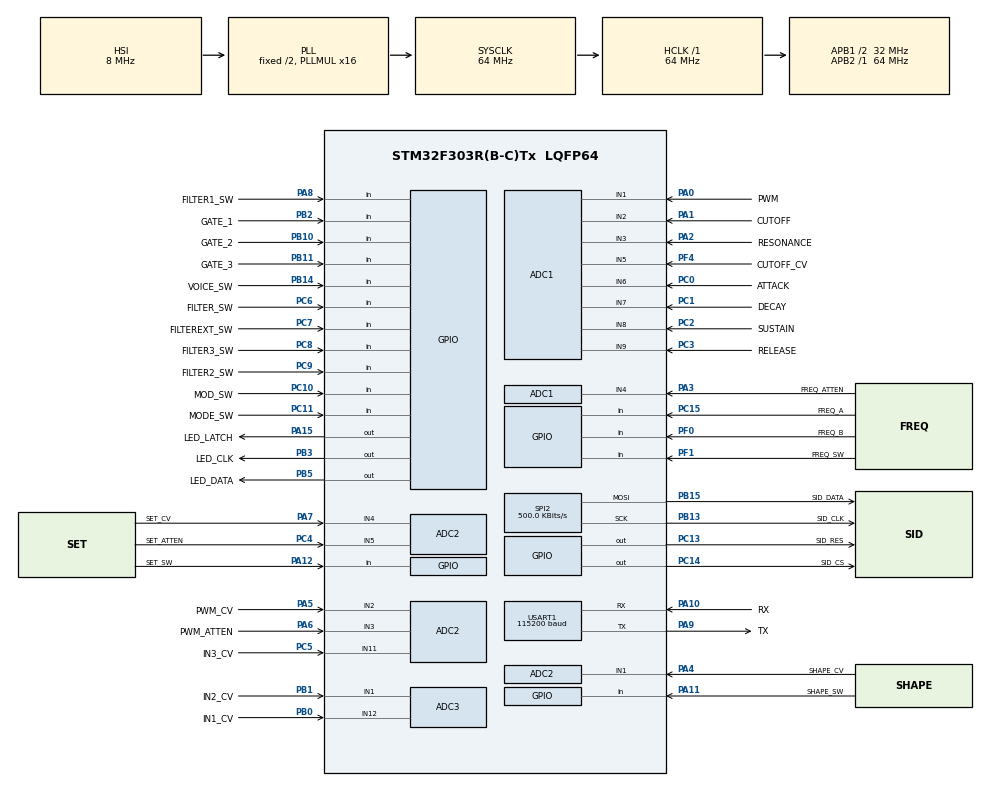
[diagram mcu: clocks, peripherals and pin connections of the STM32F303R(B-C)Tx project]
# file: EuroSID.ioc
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ADC1.Channel-0\#ChannelRegularConversion=ADC_CHANNEL_1
ADC1.Channel-1\#ChannelRegularConversion=ADC_CHANNEL_2
ADC1.Channel-2\#ChannelRegularConversion=ADC_CHANNEL_3
ADC1.Channel-3\#ChannelRegularConversion=ADC_CHANNEL_4
ADC1.Channel-4\#ChannelRegularConversion=ADC_CHANNEL_5
ADC1.Channel-5\#ChannelRegularConversion=ADC_CHANNEL_6
ADC1.Channel-6\#ChannelRegularConversion=ADC_CHANNEL_7
ADC1.Channel-7\#ChannelRegularConversion=ADC_CHANNEL_8
ADC1.Channel-8\#ChannelRegularConversion=ADC_CHANNEL_9
ADC1.ClockPrescaler=ADC_CLOCK_SYNC_PCLK_DIV4
ADC1.ContinuousConvMode=ENABLE
ADC1.DMAContinuousRequests=ENABLE
ADC1.EOCSelection=ADC_EOC_SINGLE_CONV
ADC1.NbrOfConversion=9
ADC1.NbrOfConversionFlag=1
ADC1.Offset-0\#ChannelRegularConversion=0
ADC1.Offset-1\#ChannelRegularConversion=0
ADC1.Offset-2\#ChannelRegularConversion=0
ADC1.Offset-3\#ChannelRegularConversion=0
ADC1.Offset-4\#ChannelRegularConversion=0
ADC1.Offset-5\#ChannelRegularConversion=0
ADC1.Offset-6\#ChannelRegularConversion=0
ADC1.Offset-7\#ChannelRegularConversion=0
ADC1.Offset-8\#ChannelRegularConversion=0
ADC1.OffsetNumber-0\#ChannelRegularConversion=ADC_OFFSET_NONE
ADC1.OffsetNumber-1\#ChannelRegularConversion=ADC_OFFSET_NONE
ADC1.OffsetNumber-2\#ChannelRegularConversion=ADC_OFFSET_NONE
ADC1.OffsetNumber-3\#ChannelRegularConversion=ADC_OFFSET_NONE
ADC1.OffsetNumber-4\#ChannelRegularConversion=ADC_OFFSET_NONE
ADC1.OffsetNumber-5\#ChannelRegularConversion=ADC_OFFSET_NONE
ADC1.OffsetNumber-6\#ChannelRegularConversion=ADC_OFFSET_NONE
ADC1.OffsetNumber-7\#ChannelRegularConversion=ADC_OFFSET_NONE
ADC1.OffsetNumber-8\#ChannelRegularConversion=ADC_OFFSET_NONE
ADC1.Rank-0\#ChannelRegularConversion=1
ADC1.Rank-1\#ChannelRegularConversion=2
ADC1.Rank-2\#ChannelRegularConversion=3
ADC1.Rank-3\#ChannelRegularConversion=4
ADC1.Rank-4\#ChannelRegularConversion=5
ADC1.Rank-5\#ChannelRegularConversion=6
ADC1.Rank-6\#ChannelRegularConversion=7
ADC1.Rank-7\#ChannelRegularConversion=8
ADC1.Rank-8\#ChannelRegularConversion=9
ADC1.SamplingTime-0\#ChannelRegularConversion=ADC_SAMPLETIME_181CYCLES_5
ADC1.SamplingTime-1\#ChannelRegularConversion=ADC_SAMPLETIME_181CYCLES_5
ADC1.SamplingTime-2\#ChannelRegularConversion=ADC_SAMPLETIME_181CYCLES_5
ADC1.SamplingTime-3\#ChannelRegularConversion=ADC_SAMPLETIME_181CYCLES_5
ADC1.SamplingTime-4\#ChannelRegularConversion=ADC_SAMPLETIME_181CYCLES_5
ADC1.SamplingTime-5\#ChannelRegularConversion=ADC_SAMPLETIME_181CYCLES_5
ADC1.SamplingTime-6\#ChannelRegularConversion=ADC_SAMPLETIME_181CYCLES_5
ADC1.SamplingTime-7\#ChannelRegularConversion=ADC_SAMPLETIME_181CYCLES_5
ADC1.SamplingTime-8\#ChannelRegularConversion=ADC_SAMPLETIME_181CYCLES_5
ADC1.master=1
ADC2.Channel-0\#ChannelRegularConversion=ADC_CHANNEL_1
ADC2.Channel-1\#ChannelRegularConversion=ADC_CHANNEL_2
ADC2.Channel-2\#ChannelRegularConversion=ADC_CHANNEL_3
ADC2.Channel-3\#ChannelRegularConversion=ADC_CHANNEL_4
ADC2.Channel-4\#ChannelRegularConversion=ADC_CHANNEL_5
ADC2.Channel-5\#ChannelRegularConversion=ADC_CHANNEL_11
ADC2.ClockPrescaler=ADC_CLOCK_SYNC_PCLK_DIV4
ADC2.ContinuousConvMode=ENABLE
ADC2.DMAContinuousRequests=ENABLE
ADC2.EOCSelection=ADC_EOC_SINGLE_CONV
ADC2.NbrOfConversion=6
ADC2.NbrOfConversionFlag=1
ADC2.Offset-0\#ChannelRegularConversion=0
ADC2.Offset-1\#ChannelRegularConversion=0
ADC2.Offset-2\#ChannelRegularConversion=0
ADC2.Offset-3\#ChannelRegularConversion=0
ADC2.Offset-4\#ChannelRegularConversion=0
ADC2.Offset-5\#ChannelRegularConversion=0
ADC2.OffsetNumber-0\#ChannelRegularConversion=ADC_OFFSET_NONE
ADC2.OffsetNumber-1\#ChannelRegularConversion=ADC_OFFSET_NONE
ADC2.OffsetNumber-2\#ChannelRegularConversion=ADC_OFFSET_NONE
ADC2.OffsetNumber-3\#ChannelRegularConversion=ADC_OFFSET_NONE
ADC2.OffsetNumber-4\#ChannelRegularConversion=ADC_OFFSET_NONE
ADC2.OffsetNumber-5\#ChannelRegularConversion=ADC_OFFSET_NONE
ADC2.Rank-0\#ChannelRegularConversion=1
ADC2.Rank-1\#ChannelRegularConversion=2
ADC2.Rank-2\#ChannelRegularConversion=3
ADC2.Rank-3\#ChannelRegularConversion=4
ADC2.Rank-4\#ChannelRegularConversion=5
ADC2.Rank-5\#ChannelRegularConversion=6
ADC2.SamplingTime-0\#ChannelRegularConversion=ADC_SAMPLETIME_181CYCLES_5
ADC2.SamplingTime-1\#ChannelRegularConversion=ADC_SAMPLETIME_181CYCLES_5
ADC2.SamplingTime-2\#ChannelRegularConversion=ADC_SAMPLETIME_181CYCLES_5
ADC2.SamplingTime-3\#ChannelRegularConversion=ADC_SAMPLETIME_181CYCLES_5
ADC2.SamplingTime-4\#ChannelRegularConversion=ADC_SAMPLETIME_181CYCLES_5
ADC2.SamplingTime-5\#ChannelRegularConversion=ADC_SAMPLETIME_181CYCLES_5
ADC3.Channel-0\#ChannelRegularConversion=ADC_CHANNEL_1
ADC3.Channel-1\#ChannelRegularConversion=ADC_CHANNEL_12
ADC3.ClockPrescaler=ADC_CLOCK_SYNC_PCLK_DIV4
ADC3.ContinuousConvMode=ENABLE
ADC3.DMAContinuousRequests=ENABLE
ADC3.EOCSelection=ADC_EOC_SINGLE_CONV
ADC3.NbrOfConversion=2
ADC3.NbrOfConversionFlag=1
ADC3.Offset-0\#ChannelRegularConversion=0
ADC3.Offset-1\#ChannelRegularConversion=0
ADC3.OffsetNumber-0\#ChannelRegularConversion=ADC_OFFSET_NONE
ADC3.OffsetNumber-1\#ChannelRegularConversion=ADC_OFFSET_NONE
ADC3.Rank-0\#ChannelRegularConversion=1
ADC3.Rank-1\#ChannelRegularConversion=2
ADC3.SamplingTime-0\#ChannelRegularConversion=ADC_SAMPLETIME_181CYCLES_5
ADC3.SamplingTime-1\#ChannelRegularConversion=ADC_SAMPLETIME_181CYCLES_5
ADC3.master=1
Dma.ADC1.0.Direction=DMA_PERIPH_TO_MEMORY
Dma.ADC1.0.Instance=DMA1_Channel1
Dma.ADC1.0.MemDataAlignment=DMA_MDATAALIGN_HALFWORD
Dma.ADC1.0.MemInc=DMA_MINC_ENABLE
Dma.ADC1.0.Mode=DMA_CIRCULAR
Dma.ADC1.0.PeriphDataAlignment=DMA_PDATAALIGN_HALFWORD
Dma.ADC1.0.PeriphInc=DMA_PINC_DISABLE
Dma.ADC1.0.Priority=DMA_PRIORITY_MEDIUM
Dma.ADC2.1.Direction=DMA_PERIPH_TO_MEMORY
Dma.ADC2.1.Instance=DMA2_Channel3
Dma.ADC2.1.MemDataAlignment=DMA_MDATAALIGN_HALFWORD
Dma.ADC2.1.MemInc=DMA_MINC_ENABLE
Dma.ADC2.1.Mode=DMA_CIRCULAR
Dma.ADC2.1.PeriphDataAlignment=DMA_PDATAALIGN_HALFWORD
Dma.ADC2.1.PeriphInc=DMA_PINC_DISABLE
Dma.ADC2.1.Priority=DMA_PRIORITY_MEDIUM
Dma.ADC3.2.Direction=DMA_PERIPH_TO_MEMORY
Dma.ADC3.2.Instance=DMA2_Channel5
Dma.ADC3.2.MemDataAlignment=DMA_MDATAALIGN_HALFWORD
Dma.ADC3.2.MemInc=DMA_MINC_ENABLE
Dma.ADC3.2.Mode=DMA_CIRCULAR
Dma.ADC3.2.PeriphDataAlignment=DMA_PDATAALIGN_HALFWORD
Dma.ADC3.2.PeriphInc=DMA_PINC_DISABLE
Dma.ADC3.2.Priority=DMA_PRIORITY_MEDIUM
Dma.Request0=ADC1
Dma.Request1=ADC2
Dma.Request2=ADC3
Mcu.Family=STM32F3
Mcu.Name=STM32F303R(B-C)Tx
Mcu.Package=LQFP64
NVIC.DMA1_Channel1_IRQn=true\:0\:0\:false\:false\:true\:true\:false
NVIC.DMA2_Channel3_IRQn=true\:0\:0\:false\:false\:true\:true\:false
NVIC.DMA2_Channel5_IRQn=true\:0\:0\:false\:false\:true\:true\:false
NVIC.PriorityGroup=NVIC_PRIORITYGROUP_4
NVIC.TIM6_DAC_IRQn=true\:0\:0\:false\:false\:true\:false\:true
NVIC.TimeBase=TIM6_DAC_IRQn
NVIC.TimeBaseIP=TIM6
PA0.GPIO_Label=PWM
PA0.Mode=IN1-Single-Ended
PA0.Signal=ADC1_IN1
PA1.GPIO_Label=CUTOFF
PA1.Mode=IN2-Single-Ended
PA1.Signal=ADC1_IN2
PA10.GPIO_Label=RX
PA10.Mode=Asynchronous
PA10.Signal=USART1_RX
PA11.GPIO_Label=SHAPE_SW
PA11.Signal=GPIO_Input
PA12.GPIO_Label=SET_SW
PA12.Signal=GPIO_Input
PA13.GPIO_Label=SWDIO
PA13.Mode=Serial_Wire
PA13.Signal=SYS_JTMS-SWDIO
PA14.GPIO_Label=SWCLK
PA14.Mode=Serial_Wire
PA14.Signal=SYS_JTCK-SWCLK
PA15.GPIO_Label=LED_LATCH
PA15.Signal=GPIO_Output
PA2.GPIO_Label=RESONANCE
PA2.Mode=IN3-Single-Ended
PA2.Signal=ADC1_IN3
PA3.GPIO_Label=FREQ_ATTEN
PA3.Mode=IN4-Single-Ended
PA3.Signal=ADC1_IN4
PA4.GPIO_Label=SHAPE_CV
PA4.Mode=IN1-Single-Ended
PA4.Signal=ADC2_IN1
PA5.GPIO_Label=PWM_CV
PA5.Mode=IN2-Single-Ended
PA5.Signal=ADC2_IN2
PA6.GPIO_Label=PWM_ATTEN
PA6.Mode=IN3-Single-Ended
PA6.Signal=ADC2_IN3
PA7.GPIO_Label=SET_CV
PA7.Mode=IN4-Single-Ended
PA7.Signal=ADC2_IN4
PA8.GPIO_Label=FILTER1_SW
PA8.Signal=GPIO_Input
PA9.GPIO_Label=TX
PA9.Mode=Asynchronous
PA9.Signal=USART1_TX
PB0.GPIO_Label=IN1_CV
PB0.Mode=IN12-Single-Ended
PB0.Signal=ADC3_IN12
PB1.GPIO_Label=IN2_CV
PB1.Mode=IN1-Single-Ended
PB1.Signal=ADC3_IN1
PB10.GPIO_Label=GATE_2
PB10.Signal=GPIO_Input
PB11.GPIO_Label=GATE_3
PB11.Signal=GPIO_Input
PB13.GPIO_Label=SID_CLK
PB13.Mode=TX_Only_Simplex_Unidirect_Master
PB13.Signal=SPI2_SCK
PB14.GPIO_Label=VOICE_SW
PB14.Signal=GPIO_Input
PB15.GPIO_Label=SID_DATA
PB15.Mode=TX_Only_Simplex_Unidirect_Master
PB15.Signal=SPI2_MOSI
PB2.GPIO_Label=GATE_1
PB2.Signal=GPIO_Input
PB3.GPIO_Label=LED_CLK
PB3.Signal=GPIO_Output
PB5.GPIO_Label=LED_DATA
PB5.Signal=GPIO_Output
PC0.GPIO_Label=ATTACK
PC0.Signal=ADCx_IN6
PC1.GPIO_Label=DECAY
PC1.Signal=ADCx_IN7
PC10.GPIO_Label=MOD_SW
PC10.Signal=GPIO_Input
PC11.GPIO_Label=MODE_SW
PC11.Signal=GPIO_Input
PC13.GPIO_Label=SID_RES
PC13.Signal=GPIO_Output
PC14-OSC32_IN.GPIO_Label=SID_CS
PC14-OSC32_IN.Signal=GPIO_Output
PC15-OSC32_OUT.GPIO_Label=FREQ_A
PC15-OSC32_OUT.Signal=GPIO_Input
PC2.GPIO_Label=SUSTAIN
PC2.Signal=ADCx_IN8
PC3.GPIO_Label=RELEASE
PC3.Signal=ADCx_IN9
PC4.GPIO_Label=SET_ATTEN
PC4.Mode=IN5-Single-Ended
PC4.Signal=ADC2_IN5
PC5.GPIO_Label=IN3_CV
PC5.Mode=IN11-Single-Ended
PC5.Signal=ADC2_IN11
PC6.GPIO_Label=FILTER_SW
PC6.Signal=GPIO_Input
PC7.GPIO_Label=FILTEREXT_SW
PC7.Signal=GPIO_Input
PC8.GPIO_Label=FILTER3_SW
PC8.Signal=GPIO_Input
PC9.GPIO_Label=FILTER2_SW
PC9.Signal=GPIO_Input
PF0-OSC_IN.GPIO_Label=FREQ_B
PF0-OSC_IN.Signal=GPIO_Input
PF1-OSC_OUT.GPIO_Label=FREQ_SW
PF1-OSC_OUT.Signal=GPIO_Input
PF4.GPIO_Label=CUTOFF_CV
PF4.Mode=IN5-Single-Ended
PF4.Signal=ADC1_IN5
ProjectManager.HeapSize=0x200
ProjectManager.StackSize=0x400
ProjectManager.TargetToolchain=Other Toolchains (GPDSC)
RCC.AHBFreq_Value=64000000
RCC.APB1CLKDivider=RCC_HCLK_DIV2
RCC.APB1Freq_Value=32000000
RCC.APB1TimFreq_Value=64000000
RCC.APB2Freq_Value=64000000
RCC.APB2TimFreq_Value=64000000
RCC.CortexFreq_Value=64000000
RCC.HCLKFreq_Value=64000000
RCC.HSE_VALUE=8000000
RCC.HSI_VALUE=8000000
RCC.LSE_VALUE=32768
RCC.PLLMUL=RCC_PLL_MUL16
RCC.SYSCLKFreq_VALUE=64000000
RCC.SYSCLKSourceVirtual=RCC_SYSCLKSOURCE_PLLCLK
RCC.USBFreq_Value=64000000
SH.ADCx_IN6.0=ADC1_IN6,IN6-Single-Ended
SH.ADCx_IN7.0=ADC1_IN7,IN7-Single-Ended
SH.ADCx_IN8.0=ADC1_IN8,IN8-Single-Ended
SH.ADCx_IN9.0=ADC1_IN9,IN9-Single-Ended
SPI2.BaudRatePrescaler=SPI_BAUDRATEPRESCALER_64
SPI2.CalculateBaudRate=500.0 KBits/s
SPI2.DataSize=SPI_DATASIZE_13BIT
SPI2.Direction=SPI_DIRECTION_2LINES
SPI2.FirstBit=SPI_FIRSTBIT_LSB
SPI2.Mode=SPI_MODE_MASTER
SPI2.VirtualType=VM_MASTER
USART1.BaudRate=115200
USART1.VirtualMode-Asynchronous=VM_ASYNC
VP_SYS_VS_tim6.Mode=TIM6
board=custom

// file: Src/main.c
/* USER CODE BEGIN Header */
/**
  ******************************************************************************
  * @file           : main.c
  * @brief          : Main program body
  ******************************************************************************
  * @attention
  *
  * <h2><center>&copy; Copyright (c) 2019 STMicroelectronics.
  * All rights reserved.</center></h2>
  *
  * This software component is licensed by ST under BSD 3-Clause license,
  * the "License"; You may not use this file except in compliance with the
  * License. You may obtain a copy of the License at:
  *                        opensource.org/licenses/BSD-3-Clause
  *
  ******************************************************************************
  */
/* USER CODE END Header */

#include "main.h"

/* USER CODE BEGIN Includes */
#include "SID.h"
#include "TLC5947.h"
/* USER CODE END Includes */

ADC_HandleTypeDef hadc1;
ADC_HandleTypeDef hadc2;
ADC_HandleTypeDef hadc3;
DMA_HandleTypeDef hdma_adc1;
DMA_HandleTypeDef hdma_adc2;
DMA_HandleTypeDef hdma_adc3;

SPI_HandleTypeDef hspi2;

UART_HandleTypeDef huart1;

void SystemClock_Config(void);
static void MX_GPIO_Init(void);
static void MX_DMA_Init(void);
static void MX_ADC1_Init(void);
static void MX_ADC2_Init(void);
static void MX_ADC3_Init(void);
static void MX_SPI2_Init(void);
static void MX_USART1_UART_Init(void);

int main(void)
{

  /* MCU Configuration--------------------------------------------------------*/

  /* Reset of all peripherals, Initializes the Flash interface and the Systick. */
  HAL_Init();

  /* Configure the system clock */
  SystemClock_Config();

  /* Initialize all configured peripherals */
  MX_GPIO_Init();
  MX_DMA_Init();
  MX_ADC1_Init();
  MX_ADC2_Init();
  MX_ADC3_Init();
  MX_SPI2_Init();
  MX_USART1_UART_Init();

  /* Infinite loop */
  while (1)
  {

  }
}

void SystemClock_Config(void)
{
  RCC_OscInitTypeDef RCC_OscInitStruct = {0};
  RCC_ClkInitTypeDef RCC_ClkInitStruct = {0};
  RCC_PeriphCLKInitTypeDef PeriphClkInit = {0};

  /** Initializes the CPU, AHB and APB busses clocks
  */
  RCC_OscInitStruct.OscillatorType = RCC_OSCILLATORTYPE_HSI;
  RCC_OscInitStruct.HSIState = RCC_HSI_ON;
  RCC_OscInitStruct.HSICalibrationValue = RCC_HSICALIBRATION_DEFAULT;
  RCC_OscInitStruct.PLL.PLLState = RCC_PLL_ON;
  RCC_OscInitStruct.PLL.PLLSource = RCC_PLLSOURCE_HSI;
  RCC_OscInitStruct.PLL.PLLMUL = RCC_PLL_MUL16;
  if (HAL_RCC_OscConfig(&RCC_OscInitStruct) != HAL_OK)
  {
    Error_Handler();
  }
  /** Initializes the CPU, AHB and APB busses clocks
  */
  RCC_ClkInitStruct.ClockType = RCC_CLOCKTYPE_HCLK|RCC_CLOCKTYPE_SYSCLK
                              |RCC_CLOCKTYPE_PCLK1|RCC_CLOCKTYPE_PCLK2;
  RCC_ClkInitStruct.SYSCLKSource = RCC_SYSCLKSOURCE_PLLCLK;
  RCC_ClkInitStruct.AHBCLKDivider = RCC_SYSCLK_DIV1;
  RCC_ClkInitStruct.APB1CLKDivider = RCC_HCLK_DIV2;
  RCC_ClkInitStruct.APB2CLKDivider = RCC_HCLK_DIV1;

  if (HAL_RCC_ClockConfig(&RCC_ClkInitStruct, FLASH_LATENCY_2) != HAL_OK)
  {
    Error_Handler();
  }
  PeriphClkInit.PeriphClockSelection = RCC_PERIPHCLK_USART1;
  PeriphClkInit.Usart1ClockSelection = RCC_USART1CLKSOURCE_PCLK2;
  if (HAL_RCCEx_PeriphCLKConfig(&PeriphClkInit) != HAL_OK)
  {
    Error_Handler();
  }
}

static void MX_ADC1_Init(void)
{

  ADC_MultiModeTypeDef multimode = {0};
  ADC_ChannelConfTypeDef sConfig = {0};

  /** Common config
  */
  hadc1.Instance = ADC1;
  hadc1.Init.ClockPrescaler = ADC_CLOCK_SYNC_PCLK_DIV4;
  hadc1.Init.Resolution = ADC_RESOLUTION_12B;
  hadc1.Init.ScanConvMode = ADC_SCAN_ENABLE;
  hadc1.Init.ContinuousConvMode = ENABLE;
  hadc1.Init.DiscontinuousConvMode = DISABLE;
  hadc1.Init.ExternalTrigConvEdge = ADC_EXTERNALTRIGCONVEDGE_NONE;
  hadc1.Init.ExternalTrigConv = ADC_SOFTWARE_START;
  hadc1.Init.DataAlign = ADC_DATAALIGN_RIGHT;
  hadc1.Init.NbrOfConversion = 9;
  hadc1.Init.DMAContinuousRequests = ENABLE;
  hadc1.Init.EOCSelection = ADC_EOC_SINGLE_CONV;
  hadc1.Init.LowPowerAutoWait = DISABLE;
  hadc1.Init.Overrun = ADC_OVR_DATA_OVERWRITTEN;
  if (HAL_ADC_Init(&hadc1) != HAL_OK)
  {
    Error_Handler();
  }
  /** Configure the ADC multi-mode
  */
  multimode.Mode = ADC_MODE_INDEPENDENT;
  if (HAL_ADCEx_MultiModeConfigChannel(&hadc1, &multimode) != HAL_OK)
  {
    Error_Handler();
  }
  /** Configure Regular Channel
  */
  sConfig.Channel = ADC_CHANNEL_1;
  sConfig.Rank = ADC_REGULAR_RANK_1;
  sConfig.SingleDiff = ADC_SINGLE_ENDED;
  sConfig.SamplingTime = ADC_SAMPLETIME_181CYCLES_5;
  sConfig.OffsetNumber = ADC_OFFSET_NONE;
  sConfig.Offset = 0;
  if (HAL_ADC_ConfigChannel(&hadc1, &sConfig) != HAL_OK)
  {
    Error_Handler();
  }
  /** Configure Regular Channel
  */
  sConfig.Channel = ADC_CHANNEL_2;
  sConfig.Rank = ADC_REGULAR_RANK_2;
  if (HAL_ADC_ConfigChannel(&hadc1, &sConfig) != HAL_OK)
  {
    Error_Handler();
  }
  /** Configure Regular Channel
  */
  sConfig.Channel = ADC_CHANNEL_3;
  sConfig.Rank = ADC_REGULAR_RANK_3;
  if (HAL_ADC_ConfigChannel(&hadc1, &sConfig) != HAL_OK)
  {
    Error_Handler();
  }
  /** Configure Regular Channel
  */
  sConfig.Channel = ADC_CHANNEL_4;
  sConfig.Rank = ADC_REGULAR_RANK_4;
  if (HAL_ADC_ConfigChannel(&hadc1, &sConfig) != HAL_OK)
  {
    Error_Handler();
  }
  /** Configure Regular Channel
  */
  sConfig.Channel = ADC_CHANNEL_5;
  sConfig.Rank = ADC_REGULAR_RANK_5;
  if (HAL_ADC_ConfigChannel(&hadc1, &sConfig) != HAL_OK)
  {
    Error_Handler();
  }
  /** Configure Regular Channel
  */
  sConfig.Channel = ADC_CHANNEL_6;
  sConfig.Rank = ADC_REGULAR_RANK_6;
  if (HAL_ADC_ConfigChannel(&hadc1, &sConfig) != HAL_OK)
  {
    Error_Handler();
  }
  /** Configure Regular Channel
  */
  sConfig.Channel = ADC_CHANNEL_7;
  sConfig.Rank = ADC_REGULAR_RANK_7;
  if (HAL_ADC_ConfigChannel(&hadc1, &sConfig) != HAL_OK)
  {
    Error_Handler();
  }
  /** Configure Regular Channel
  */
  sConfig.Channel = ADC_CHANNEL_8;
  sConfig.Rank = ADC_REGULAR_RANK_8;
  if (HAL_ADC_ConfigChannel(&hadc1, &sConfig) != HAL_OK)
  {
    Error_Handler();
  }
  /** Configure Regular Channel
  */
  sConfig.Channel = ADC_CHANNEL_9;
  sConfig.Rank = ADC_REGULAR_RANK_9;
  if (HAL_ADC_ConfigChannel(&hadc1, &sConfig) != HAL_OK)
  {
    Error_Handler();
  }

}

static void MX_ADC2_Init(void)
{

  ADC_ChannelConfTypeDef sConfig = {0};

  /** Common config
  */
  hadc2.Instance = ADC2;
  hadc2.Init.ClockPrescaler = ADC_CLOCK_SYNC_PCLK_DIV4;
  hadc2.Init.Resolution = ADC_RESOLUTION_12B;
  hadc2.Init.ScanConvMode = ADC_SCAN_ENABLE;
  hadc2.Init.ContinuousConvMode = ENABLE;
  hadc2.Init.DiscontinuousConvMode = DISABLE;
  hadc2.Init.ExternalTrigConvEdge = ADC_EXTERNALTRIGCONVEDGE_NONE;
  hadc2.Init.ExternalTrigConv = ADC_SOFTWARE_START;
  hadc2.Init.DataAlign = ADC_DATAALIGN_RIGHT;
  hadc2.Init.NbrOfConversion = 6;
  hadc2.Init.DMAContinuousRequests = ENABLE;
  hadc2.Init.EOCSelection = ADC_EOC_SINGLE_CONV;
  hadc2.Init.LowPowerAutoWait = DISABLE;
  hadc2.Init.Overrun = ADC_OVR_DATA_OVERWRITTEN;
  if (HAL_ADC_Init(&hadc2) != HAL_OK)
  {
    Error_Handler();
  }
  /** Configure Regular Channel
  */
  sConfig.Channel = ADC_CHANNEL_1;
  sConfig.Rank = ADC_REGULAR_RANK_1;
  sConfig.SingleDiff = ADC_SINGLE_ENDED;
  sConfig.SamplingTime = ADC_SAMPLETIME_181CYCLES_5;
  sConfig.OffsetNumber = ADC_OFFSET_NONE;
  sConfig.Offset = 0;
  if (HAL_ADC_ConfigChannel(&hadc2, &sConfig) != HAL_OK)
  {
    Error_Handler();
  }
  /** Configure Regular Channel
  */
  sConfig.Channel = ADC_CHANNEL_2;
  sConfig.Rank = ADC_REGULAR_RANK_2;
  if (HAL_ADC_ConfigChannel(&hadc2, &sConfig) != HAL_OK)
  {
    Error_Handler();
  }
  /** Configure Regular Channel
  */
  sConfig.Channel = ADC_CHANNEL_3;
  sConfig.Rank = ADC_REGULAR_RANK_3;
  if (HAL_ADC_ConfigChannel(&hadc2, &sConfig) != HAL_OK)
  {
    Error_Handler();
  }
  /** Configure Regular Channel
  */
  sConfig.Channel = ADC_CHANNEL_4;
  sConfig.Rank = ADC_REGULAR_RANK_4;
  if (HAL_ADC_ConfigChannel(&hadc2, &sConfig) != HAL_OK)
  {
    Error_Handler();
  }
  /** Configure Regular Channel
  */
  sConfig.Channel = ADC_CHANNEL_5;
  sConfig.Rank = ADC_REGULAR_RANK_5;
  if (HAL_ADC_ConfigChannel(&hadc2, &sConfig) != HAL_OK)
  {
    Error_Handler();
  }
  /** Configure Regular Channel
  */
  sConfig.Channel = ADC_CHANNEL_11;
  sConfig.Rank = ADC_REGULAR_RANK_6;
  if (HAL_ADC_ConfigChannel(&hadc2, &sConfig) != HAL_OK)
  {
    Error_Handler();
  }

}

static void MX_ADC3_Init(void)
{

  ADC_MultiModeTypeDef multimode = {0};
  ADC_ChannelConfTypeDef sConfig = {0};

  /** Common config
  */
  hadc3.Instance = ADC3;
  hadc3.Init.ClockPrescaler = ADC_CLOCK_SYNC_PCLK_DIV4;
  hadc3.Init.Resolution = ADC_RESOLUTION_12B;
  hadc3.Init.ScanConvMode = ADC_SCAN_ENABLE;
  hadc3.Init.ContinuousConvMode = ENABLE;
  hadc3.Init.DiscontinuousConvMode = DISABLE;
  hadc3.Init.ExternalTrigConvEdge = ADC_EXTERNALTRIGCONVEDGE_NONE;
  hadc3.Init.ExternalTrigConv = ADC_SOFTWARE_START;
  hadc3.Init.DataAlign = ADC_DATAALIGN_RIGHT;
  hadc3.Init.NbrOfConversion = 2;
  hadc3.Init.DMAContinuousRequests = ENABLE;
  hadc3.Init.EOCSelection = ADC_EOC_SINGLE_CONV;
  hadc3.Init.LowPowerAutoWait = DISABLE;
  hadc3.Init.Overrun = ADC_OVR_DATA_OVERWRITTEN;
  if (HAL_ADC_Init(&hadc3) != HAL_OK)
  {
    Error_Handler();
  }
  /** Configure the ADC multi-mode
  */
  multimode.Mode = ADC_MODE_INDEPENDENT;
  if (HAL_ADCEx_MultiModeConfigChannel(&hadc3, &multimode) != HAL_OK)
  {
    Error_Handler();
  }
  /** Configure Regular Channel
  */
  sConfig.Channel = ADC_CHANNEL_1;
  sConfig.Rank = ADC_REGULAR_RANK_1;
  sConfig.SingleDiff = ADC_SINGLE_ENDED;
  sConfig.SamplingTime = ADC_SAMPLETIME_181CYCLES_5;
  sConfig.OffsetNumber = ADC_OFFSET_NONE;
  sConfig.Offset = 0;
  if (HAL_ADC_ConfigChannel(&hadc3, &sConfig) != HAL_OK)
  {
    Error_Handler();
  }
  /** Configure Regular Channel
  */
  sConfig.Channel = ADC_CHANNEL_12;
  sConfig.Rank = ADC_REGULAR_RANK_2;
  if (HAL_ADC_ConfigChannel(&hadc3, &sConfig) != HAL_OK)
  {
    Error_Handler();
  }

}

static void MX_SPI2_Init(void)
{

  /* SPI2 parameter configuration*/
  hspi2.Instance = SPI2;
  hspi2.Init.Mode = SPI_MODE_MASTER;
  hspi2.Init.Direction = SPI_DIRECTION_2LINES;
  hspi2.Init.DataSize = SPI_DATASIZE_13BIT;
  hspi2.Init.CLKPolarity = SPI_POLARITY_LOW;
  hspi2.Init.CLKPhase = SPI_PHASE_1EDGE;
  hspi2.Init.NSS = SPI_NSS_SOFT;
  hspi2.Init.BaudRatePrescaler = SPI_BAUDRATEPRESCALER_64;
  hspi2.Init.FirstBit = SPI_FIRSTBIT_LSB;
  hspi2.Init.TIMode = SPI_TIMODE_DISABLE;
  hspi2.Init.CRCCalculation = SPI_CRCCALCULATION_DISABLE;
  hspi2.Init.CRCPolynomial = 7;
  hspi2.Init.CRCLength = SPI_CRC_LENGTH_DATASIZE;
  hspi2.Init.NSSPMode = SPI_NSS_PULSE_ENABLE;
  if (HAL_SPI_Init(&hspi2) != HAL_OK)
  {
    Error_Handler();
  }

}

static void MX_USART1_UART_Init(void)
{

  huart1.Instance = USART1;
  huart1.Init.BaudRate = 115200;
  huart1.Init.WordLength = UART_WORDLENGTH_8B;
  huart1.Init.StopBits = UART_STOPBITS_1;
  huart1.Init.Parity = UART_PARITY_NONE;
  huart1.Init.Mode = UART_MODE_TX_RX;
  huart1.Init.HwFlowCtl = UART_HWCONTROL_NONE;
  huart1.Init.OverSampling = UART_OVERSAMPLING_16;
  huart1.Init.OneBitSampling = UART_ONE_BIT_SAMPLE_DISABLE;
  huart1.AdvancedInit.AdvFeatureInit = UART_ADVFEATURE_NO_INIT;
  if (HAL_UART_Init(&huart1) != HAL_OK)
  {
    Error_Handler();
  }

}

static void MX_DMA_Init(void)
{

  /* DMA controller clock enable */
  __HAL_RCC_DMA1_CLK_ENABLE();
  __HAL_RCC_DMA2_CLK_ENABLE();

  /* DMA interrupt init */
  /* DMA1_Channel1_IRQn interrupt configuration */
  HAL_NVIC_SetPriority(DMA1_Channel1_IRQn, 0, 0);
  HAL_NVIC_EnableIRQ(DMA1_Channel1_IRQn);
  /* DMA2_Channel3_IRQn interrupt configuration */
  HAL_NVIC_SetPriority(DMA2_Channel3_IRQn, 0, 0);
  HAL_NVIC_EnableIRQ(DMA2_Channel3_IRQn);
  /* DMA2_Channel5_IRQn interrupt configuration */
  HAL_NVIC_SetPriority(DMA2_Channel5_IRQn, 0, 0);
  HAL_NVIC_EnableIRQ(DMA2_Channel5_IRQn);

}

static void MX_GPIO_Init(void)
{
  GPIO_InitTypeDef GPIO_InitStruct = {0};

  /* GPIO Ports Clock Enable */
  __HAL_RCC_GPIOC_CLK_ENABLE();
  __HAL_RCC_GPIOF_CLK_ENABLE();
  __HAL_RCC_GPIOA_CLK_ENABLE();
  __HAL_RCC_GPIOB_CLK_ENABLE();

  /*Configure GPIO pin Output Level */
  HAL_GPIO_WritePin(GPIOC, SID_RES_Pin|SID_CS_Pin, GPIO_PIN_RESET);

  /*Configure GPIO pin Output Level */
  HAL_GPIO_WritePin(LED_LATCH_GPIO_Port, LED_LATCH_Pin, GPIO_PIN_RESET);

  /*Configure GPIO pin Output Level */
  HAL_GPIO_WritePin(GPIOB, LED_CLK_Pin|LED_DATA_Pin, GPIO_PIN_RESET);

  /*Configure GPIO pins : SID_RES_Pin SID_CS_Pin */
  GPIO_InitStruct.Pin = SID_RES_Pin|SID_CS_Pin;
  GPIO_InitStruct.Mode = GPIO_MODE_OUTPUT_PP;
  GPIO_InitStruct.Pull = GPIO_NOPULL;
  GPIO_InitStruct.Speed = GPIO_SPEED_FREQ_LOW;
  HAL_GPIO_Init(GPIOC, &GPIO_InitStruct);

  /*Configure GPIO pins : FREQ_A_Pin FILTER_SW_Pin FILTEREXT_SW_Pin FILTER3_SW_Pin
                           FILTER2_SW_Pin MOD_SW_Pin MODE_SW_Pin */
  GPIO_InitStruct.Pin = FREQ_A_Pin|FILTER_SW_Pin|FILTEREXT_SW_Pin|FILTER3_SW_Pin
                          |FILTER2_SW_Pin|MOD_SW_Pin|MODE_SW_Pin;
  GPIO_InitStruct.Mode = GPIO_MODE_INPUT;
  GPIO_InitStruct.Pull = GPIO_NOPULL;
  HAL_GPIO_Init(GPIOC, &GPIO_InitStruct);

  /*Configure GPIO pins : FREQ_B_Pin FREQ_SW_Pin */
  GPIO_InitStruct.Pin = FREQ_B_Pin|FREQ_SW_Pin;
  GPIO_InitStruct.Mode = GPIO_MODE_INPUT;
  GPIO_InitStruct.Pull = GPIO_NOPULL;
  HAL_GPIO_Init(GPIOF, &GPIO_InitStruct);

  /*Configure GPIO pins : GATE_1_Pin GATE_2_Pin GATE_3_Pin VOICE_SW_Pin */
  GPIO_InitStruct.Pin = GATE_1_Pin|GATE_2_Pin|GATE_3_Pin|VOICE_SW_Pin;
  GPIO_InitStruct.Mode = GPIO_MODE_INPUT;
  GPIO_InitStruct.Pull = GPIO_NOPULL;
  HAL_GPIO_Init(GPIOB, &GPIO_InitStruct);

  /*Configure GPIO pins : FILTER1_SW_Pin SHAPE_SW_Pin SET_SW_Pin */
  GPIO_InitStruct.Pin = FILTER1_SW_Pin|SHAPE_SW_Pin|SET_SW_Pin;
  GPIO_InitStruct.Mode = GPIO_MODE_INPUT;
  GPIO_InitStruct.Pull = GPIO_NOPULL;
  HAL_GPIO_Init(GPIOA, &GPIO_InitStruct);

  /*Configure GPIO pin : LED_LATCH_Pin */
  GPIO_InitStruct.Pin = LED_LATCH_Pin;
  GPIO_InitStruct.Mode = GPIO_MODE_OUTPUT_PP;
  GPIO_InitStruct.Pull = GPIO_NOPULL;
  GPIO_InitStruct.Speed = GPIO_SPEED_FREQ_LOW;
  HAL_GPIO_Init(LED_LATCH_GPIO_Port, &GPIO_InitStruct);

  /*Configure GPIO pins : LED_CLK_Pin LED_DATA_Pin */
  GPIO_InitStruct.Pin = LED_CLK_Pin|LED_DATA_Pin;
  GPIO_InitStruct.Mode = GPIO_MODE_OUTPUT_PP;
  GPIO_InitStruct.Pull = GPIO_NOPULL;
  GPIO_InitStruct.Speed = GPIO_SPEED_FREQ_LOW;
  HAL_GPIO_Init(GPIOB, &GPIO_InitStruct);

}

void HAL_TIM_PeriodElapsedCallback(TIM_HandleTypeDef *htim)
{
  if (htim->Instance == TIM6) {
    HAL_IncTick();
  }
}

void Error_Handler(void)
{
}

/************************ (C) COPYRIGHT STMicroelectronics *****END OF FILE****/
